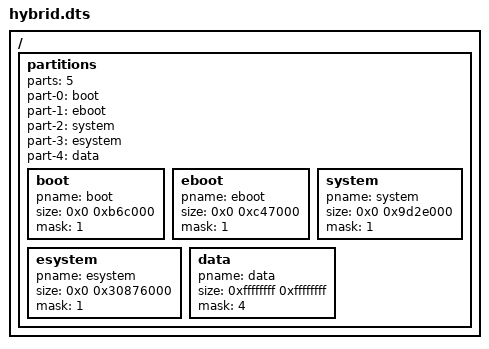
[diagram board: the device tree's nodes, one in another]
/*
 * Amlogic Ltd. GXBaby Plaform
 *
 */

/dts-v1/;

#include "gxbb_p200_1G_mibox3.dtsi"
/ {
	partitions: partitions{
		parts = <5>;
		part-0 = <&boot>;
		part-1 = <&eboot>;
		part-2 = <&system>;
		part-3 = <&esystem>;
		part-4 = <&data>;
		boot:boot{	// CoreELEC kernel
			pname = "boot";
			size = <0x0 0xb6c000>;
			mask = <1>;
		};
		eboot:eboot{	// EmuELEC kernel
			pname = "eboot";
			size = <0x0 0xc47000>;
			mask = <1>;
		};
		system:system{	// CoreELEC system
			pname = "system";
			size = <0x0 0x9d2e000>;
			mask = <1>;
		};
		esystem:esystem{	// EmuELEC system
			pname = "esystem";
			size = <0x0 0x30876000>;
			mask = <1>;
		};
		data:data
		{
			pname = "data";
			size = <0xffffffff 0xffffffff>;
			mask = <4>;
		};
	};
};
